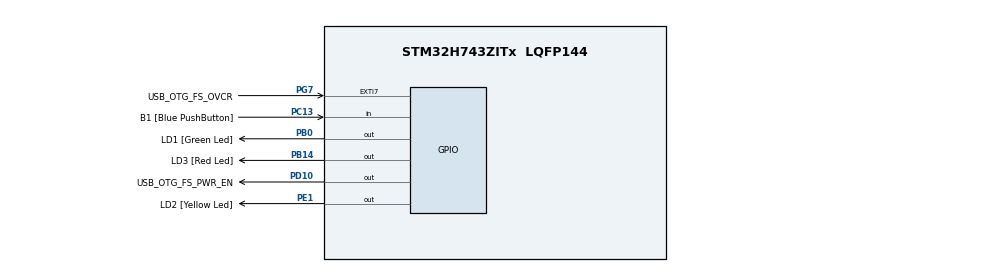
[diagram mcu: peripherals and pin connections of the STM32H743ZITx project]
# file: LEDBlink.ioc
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Mcu.Family=STM32H7
RCC.CortexFreq_Value=64000000
PH0-OSC_IN\ (PH0).Signal=RCC_OSC_IN
PB14.GPIO_Label=LD3 [Red Led]
RCC.PLLFRACN=0
PB0.GPIO_Label=LD1 [Green Led]
PC13.GPIO_Label=B1 [Blue PushButton]
PB13.Signal=ETH_TXD1
PG13.Signal=ETH_TXD0
PG11.Signal=ETH_TX_EN
ProjectManager.StackSize=0x400
PA12.Signal=USB_OTG_FS_DP
RCC.HCLKFreq_Value=64000000
PD8.Signal=USART3_TX
PE1.Signal=GPIO_Output
RCC.HSE_VALUE=8000000
RCC.DIVM1=1
PA8.Signal=USB_OTG_FS_SOF
RCC.APB3Freq_Value=64000000
Mcu.Package=LQFP144
RCC.APB4Freq_Value=64000000
PC5.Signal=ETH_RXD1
RCC.DIVQ1=4
PG7.Signal=GPXTI7
PD9.GPIO_Label=STLINK_TX
PC13.Signal=GPIO_Input
PC4.Signal=ETH_RXD0
PD9.Signal=USART3_RX
PH1-OSC_OUT\ (PH1).Signal=RCC_OSC_OUT
PD8.GPIO_Label=STLINK_RX
PD10.Signal=GPIO_Output
ProjectManager.TargetToolchain=Makefile
PC15-OSC32_OUT\ (OSC32_OUT).Signal=RCC_OSC32_OUT
PA9.Signal=USB_OTG_FS_VBUS
RCC.DIVN1=24
RCC.USBFreq_Value=384000000
PD10.GPIO_Label=USB_OTG_FS_PWR_EN
PA1.Signal=ETH_REF_CLK
PB14.Signal=GPIO_Output
board=NUCLEO-H743ZI2
PE1.GPIO_Label=LD2 [Yellow Led]
RCC.APB2Freq_Value=64000000
PG7.GPIO_Label=USB_OTG_FS_OVCR
RCC.ADCFreq_Value=129000000
Mcu.Name=STM32H743ZITx
PA2.Signal=ETH_MDIO
RCC.SYSCLKFreq_VALUE=64000000
PC14-OSC32_IN\ (OSC32_IN).Signal=RCC_OSC32_IN
PA11.Signal=USB_OTG_FS_DM
ProjectManager.HeapSize=0x200
NVIC.PriorityGroup=NVIC_PRIORITYGROUP_4
RCC.APB1Freq_Value=64000000
PB0.Signal=GPIO_Output
PC1.Signal=ETH_MDC
PA7.Signal=ETH_CRS_DV

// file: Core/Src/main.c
/* USER CODE BEGIN Header */
/**
  ******************************************************************************
  * @file           : main.c
  * @brief          : Main program body
  ******************************************************************************
  * @attention
  *
  * <h2><center>&copy; Copyright (c) 2021 STMicroelectronics.
  * All rights reserved.</center></h2>
  *
  * This software component is licensed by ST under BSD 3-Clause license,
  * the "License"; You may not use this file except in compliance with the
  * License. You may obtain a copy of the License at:
  *                        opensource.org/licenses/BSD-3-Clause
  *
  ******************************************************************************
  */
/* USER CODE END Header */
#include "main.h"

void SystemClock_Config(void);
static void MX_GPIO_Init(void);

int main(void)
{

  /* MCU Configuration--------------------------------------------------------*/

  /* Reset of all peripherals, Initializes the Flash interface and the Systick. */
  HAL_Init();

  /* Configure the system clock */
  SystemClock_Config();

  /* Initialize all configured peripherals */
  MX_GPIO_Init();

  /* Infinite loop */
  while (1)
  {

    /* USER CODE BEGIN 3 */
     HAL_GPIO_TogglePin(LD2_GPIO_Port, LD2_Pin); // PORTA, PA5
     HAL_Delay(500);
  }
  /* USER CODE END 3 */
}

void SystemClock_Config(void)
{
  RCC_OscInitTypeDef RCC_OscInitStruct = {0};
  RCC_ClkInitTypeDef RCC_ClkInitStruct = {0};

  /** Supply configuration update enable
  */
  HAL_PWREx_ConfigSupply(PWR_LDO_SUPPLY);
  /** Configure the main internal regulator output voltage
  */
  __HAL_PWR_VOLTAGESCALING_CONFIG(PWR_REGULATOR_VOLTAGE_SCALE3);

  while(!__HAL_PWR_GET_FLAG(PWR_FLAG_VOSRDY)) {}
  /** Initializes the RCC Oscillators according to the specified parameters
  * in the RCC_OscInitTypeDef structure.
  */
  RCC_OscInitStruct.OscillatorType = RCC_OSCILLATORTYPE_HSI;
  RCC_OscInitStruct.HSIState = RCC_HSI_DIV1;
  RCC_OscInitStruct.HSICalibrationValue = RCC_HSICALIBRATION_DEFAULT;
  RCC_OscInitStruct.PLL.PLLState = RCC_PLL_NONE;
  if (HAL_RCC_OscConfig(&RCC_OscInitStruct) != HAL_OK)
  {
    Error_Handler();
  }
  /** Initializes the CPU, AHB and APB buses clocks
  */
  RCC_ClkInitStruct.ClockType = RCC_CLOCKTYPE_HCLK|RCC_CLOCKTYPE_SYSCLK
                              |RCC_CLOCKTYPE_PCLK1|RCC_CLOCKTYPE_PCLK2
                              |RCC_CLOCKTYPE_D3PCLK1|RCC_CLOCKTYPE_D1PCLK1;
  RCC_ClkInitStruct.SYSCLKSource = RCC_SYSCLKSOURCE_HSI;
  RCC_ClkInitStruct.SYSCLKDivider = RCC_SYSCLK_DIV1;
  RCC_ClkInitStruct.AHBCLKDivider = RCC_HCLK_DIV1;
  RCC_ClkInitStruct.APB3CLKDivider = RCC_APB3_DIV1;
  RCC_ClkInitStruct.APB1CLKDivider = RCC_APB1_DIV1;
  RCC_ClkInitStruct.APB2CLKDivider = RCC_APB2_DIV1;
  RCC_ClkInitStruct.APB4CLKDivider = RCC_APB4_DIV1;

  if (HAL_RCC_ClockConfig(&RCC_ClkInitStruct, FLASH_LATENCY_0) != HAL_OK)
  {
    Error_Handler();
  }
}

static void MX_GPIO_Init(void)
{
  GPIO_InitTypeDef GPIO_InitStruct = {0};

  /* GPIO Ports Clock Enable */
  __HAL_RCC_GPIOC_CLK_ENABLE();
  __HAL_RCC_GPIOH_CLK_ENABLE();
  __HAL_RCC_GPIOA_CLK_ENABLE();
  __HAL_RCC_GPIOB_CLK_ENABLE();
  __HAL_RCC_GPIOD_CLK_ENABLE();
  __HAL_RCC_GPIOG_CLK_ENABLE();
  __HAL_RCC_GPIOE_CLK_ENABLE();

  /*Configure GPIO pin Output Level */
  HAL_GPIO_WritePin(GPIOB, LD1_Pin|LD3_Pin, GPIO_PIN_RESET);

  /*Configure GPIO pin Output Level */
  HAL_GPIO_WritePin(USB_OTG_FS_PWR_EN_GPIO_Port, USB_OTG_FS_PWR_EN_Pin, GPIO_PIN_RESET);

  /*Configure GPIO pin Output Level */
  HAL_GPIO_WritePin(LD2_GPIO_Port, LD2_Pin, GPIO_PIN_RESET);

  /*Configure GPIO pin : B1_Pin */
  GPIO_InitStruct.Pin = B1_Pin;
  GPIO_InitStruct.Mode = GPIO_MODE_INPUT;
  GPIO_InitStruct.Pull = GPIO_NOPULL;
  HAL_GPIO_Init(B1_GPIO_Port, &GPIO_InitStruct);

  /*Configure GPIO pins : PC1 PC4 PC5 */
  GPIO_InitStruct.Pin = GPIO_PIN_1|GPIO_PIN_4|GPIO_PIN_5;
  GPIO_InitStruct.Mode = GPIO_MODE_AF_PP;
  GPIO_InitStruct.Pull = GPIO_NOPULL;
  GPIO_InitStruct.Speed = GPIO_SPEED_FREQ_LOW;
  GPIO_InitStruct.Alternate = GPIO_AF11_ETH;
  HAL_GPIO_Init(GPIOC, &GPIO_InitStruct);

  /*Configure GPIO pins : PA1 PA2 PA7 */
  GPIO_InitStruct.Pin = GPIO_PIN_1|GPIO_PIN_2|GPIO_PIN_7;
  GPIO_InitStruct.Mode = GPIO_MODE_AF_PP;
  GPIO_InitStruct.Pull = GPIO_NOPULL;
  GPIO_InitStruct.Speed = GPIO_SPEED_FREQ_LOW;
  GPIO_InitStruct.Alternate = GPIO_AF11_ETH;
  HAL_GPIO_Init(GPIOA, &GPIO_InitStruct);

  /*Configure GPIO pins : LD1_Pin LD3_Pin */
  GPIO_InitStruct.Pin = LD1_Pin|LD3_Pin;
  GPIO_InitStruct.Mode = GPIO_MODE_OUTPUT_PP;
  GPIO_InitStruct.Pull = GPIO_NOPULL;
  GPIO_InitStruct.Speed = GPIO_SPEED_FREQ_LOW;
  HAL_GPIO_Init(GPIOB, &GPIO_InitStruct);

  /*Configure GPIO pin : PB13 */
  GPIO_InitStruct.Pin = GPIO_PIN_13;
  GPIO_InitStruct.Mode = GPIO_MODE_AF_PP;
  GPIO_InitStruct.Pull = GPIO_NOPULL;
  GPIO_InitStruct.Speed = GPIO_SPEED_FREQ_LOW;
  GPIO_InitStruct.Alternate = GPIO_AF11_ETH;
  HAL_GPIO_Init(GPIOB, &GPIO_InitStruct);

  /*Configure GPIO pins : STLINK_RX_Pin STLINK_TX_Pin */
  GPIO_InitStruct.Pin = STLINK_RX_Pin|STLINK_TX_Pin;
  GPIO_InitStruct.Mode = GPIO_MODE_AF_PP;
  GPIO_InitStruct.Pull = GPIO_NOPULL;
  GPIO_InitStruct.Speed = GPIO_SPEED_FREQ_LOW;
  GPIO_InitStruct.Alternate = GPIO_AF7_USART3;
  HAL_GPIO_Init(GPIOD, &GPIO_InitStruct);

  /*Configure GPIO pin : USB_OTG_FS_PWR_EN_Pin */
  GPIO_InitStruct.Pin = USB_OTG_FS_PWR_EN_Pin;
  GPIO_InitStruct.Mode = GPIO_MODE_OUTPUT_PP;
  GPIO_InitStruct.Pull = GPIO_NOPULL;
  GPIO_InitStruct.Speed = GPIO_SPEED_FREQ_LOW;
  HAL_GPIO_Init(USB_OTG_FS_PWR_EN_GPIO_Port, &GPIO_InitStruct);

  /*Configure GPIO pin : USB_OTG_FS_OVCR_Pin */
  GPIO_InitStruct.Pin = USB_OTG_FS_OVCR_Pin;
  GPIO_InitStruct.Mode = GPIO_MODE_IT_RISING;
  GPIO_InitStruct.Pull = GPIO_NOPULL;
  HAL_GPIO_Init(USB_OTG_FS_OVCR_GPIO_Port, &GPIO_InitStruct);

  /*Configure GPIO pins : PA8 PA11 PA12 */
  GPIO_InitStruct.Pin = GPIO_PIN_8|GPIO_PIN_11|GPIO_PIN_12;
  GPIO_InitStruct.Mode = GPIO_MODE_AF_PP;
  GPIO_InitStruct.Pull = GPIO_NOPULL;
  GPIO_InitStruct.Speed = GPIO_SPEED_FREQ_LOW;
  GPIO_InitStruct.Alternate = GPIO_AF10_OTG1_FS;
  HAL_GPIO_Init(GPIOA, &GPIO_InitStruct);

  /*Configure GPIO pins : PG11 PG13 */
  GPIO_InitStruct.Pin = GPIO_PIN_11|GPIO_PIN_13;
  GPIO_InitStruct.Mode = GPIO_MODE_AF_PP;
  GPIO_InitStruct.Pull = GPIO_NOPULL;
  GPIO_InitStruct.Speed = GPIO_SPEED_FREQ_LOW;
  GPIO_InitStruct.Alternate = GPIO_AF11_ETH;
  HAL_GPIO_Init(GPIOG, &GPIO_InitStruct);

  /*Configure GPIO pin : LD2_Pin */
  GPIO_InitStruct.Pin = LD2_Pin;
  GPIO_InitStruct.Mode = GPIO_MODE_OUTPUT_PP;
  GPIO_InitStruct.Pull = GPIO_NOPULL;
  GPIO_InitStruct.Speed = GPIO_SPEED_FREQ_LOW;
  HAL_GPIO_Init(LD2_GPIO_Port, &GPIO_InitStruct);

}

void Error_Handler(void)
{
  __disable_irq();
  while (1)
  {
  }
}

/************************ (C) COPYRIGHT STMicroelectronics *****END OF FILE****/
